# wiz16b8m4ct3_0_WIZ16B8M4CT3 register map
Vendor: Texas Instruments
Registers are 32-bit, read-write, reset 0x0 unless marked. A register's access mark holds for its fields unless they carry their own. Offsets are as the file gives them; [hi:lo] are bit positions; {n}, {i} and the like mark numbered series.

## wiz16b8m4ct3_0_WIZ16B8M4CT3 (part 2 of 12)
0x00 WIZ16B8M4CT3_CMN_PID_TYPE ro reset 0x7364
  [15:0] CMN_PID_TYPE_15_0 — Product type : This field contains the ASCII codes that represent the product type sd for SerDes.
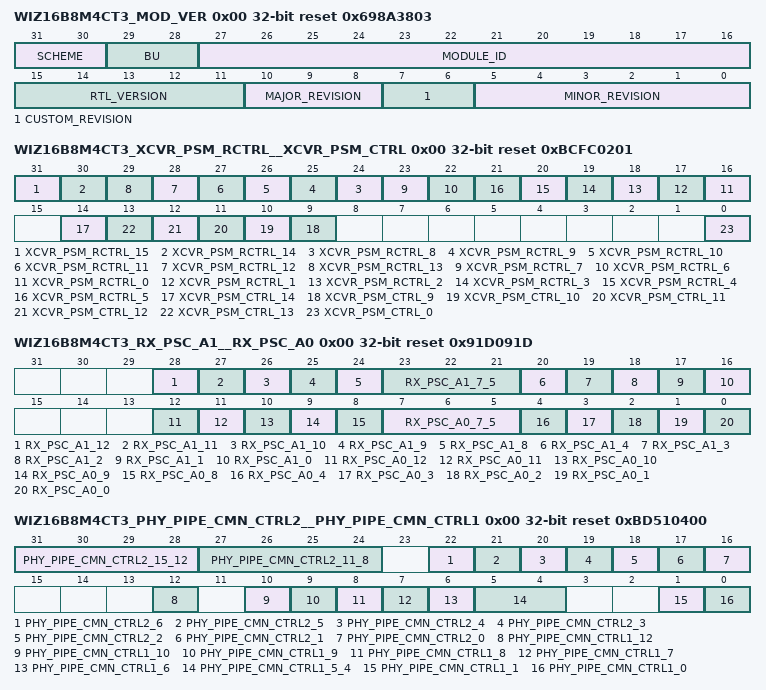
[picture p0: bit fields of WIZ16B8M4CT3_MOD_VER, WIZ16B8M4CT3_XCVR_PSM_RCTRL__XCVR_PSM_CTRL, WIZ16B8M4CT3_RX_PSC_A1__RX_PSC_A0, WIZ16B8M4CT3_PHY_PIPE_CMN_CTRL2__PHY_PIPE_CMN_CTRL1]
0x00 WIZ16B8M4CT3_MOD_VER ro reset 0x698A3803
  [31:30] SCHEME — Module Scheme
  [29:28] BU — Module Business Unit
  [27:16] MODULE_ID — WIZ16B8M4CT3 module ID.
  [15:11] RTL_VERSION
  [10:8] MAJOR_REVISION
  [7:6] CUSTOM_REVISION
  [5:0] MINOR_REVISION
0x00 WIZ16B8M4CT3_XCVR_PSM_RCTRL__XCVR_PSM_CTRL reset 0xBCFC0201
  [31] XCVR_PSM_RCTRL_15 — RX reset active ready : Controls the state the receiver reset is changed to when in the ready power state. 1'b0: Reset not active 1'b1: Reset active
  [30] XCVR_PSM_RCTRL_14 — RX reset active calibration : Controls the state the receiver reset is changed to when in the calibration power state. 1'b0: Reset not active 1'b1: Reset active
  [n+16] XCVR_PSM_RCTRL_{n} (n=8..13) — RX reset active A{n-8} : Controls the state the receiver reset is changed to when in the A{n-8} entry power state. 1'b0: Reset not active 1'b1: Reset active
  [23] XCVR_PSM_RCTRL_7 — TX reset active ready : Controls the state the transmitter reset is changed to when in the ready power state. 1'b0: Reset not active 1'b1: Reset active
  [22] XCVR_PSM_RCTRL_6 — TX reset active calibration : Controls the state the transmitter reset is changed to when in the calibration power state. 1'b0: Reset not active 1'b1: Reset active
  [n+16] XCVR_PSM_RCTRL_{n} (n=0..5) — TX reset active A{n} : Controls the state the transmitter reset is changed to when in the A{n} entry power state. 1'b0: Reset not active 1'b1: Reset active
  [14] XCVR_PSM_CTRL_14 — Bypass A0 in delay from PSM ready : When this bit is active (1'b1), the A0 input delay is bypassed when transitioning from the PSM ready state to the A0 power state. The result of this is the amount of time spent in the A0 in delay state is the value specified in the A0 in bypass timer register. The intention of this bit is to bypass the delay for cases when the required analog components being controlled are already enabled in the ready power state, and no additional delay is required when transitioning to the A0 power state.
  [n] XCVR_PSM_CTRL_{n} (n=9..13) — Bypass A0 in delay from A{n-8} : When this bit is active (1'b1), the A0 input delay is bypassed when transitioning from the A{n-8} to the A0 power state. The result of this is the amount of time spent in the A0 in delay state is the value specified in the A0 in bypass timer register. The intention of this bit is to bypass the delay for cases when the required analog components being controlled are already enabled in the A{n-8} power state, and no additional delay is required when transitioning to the A0 power state.
  [0] XCVR_PSM_CTRL_0 — Reserved - spare (must remain set to 1'b1).
0x00 WIZ16B8M4CT3_RX_PSC_A1__RX_PSC_A0 reset 0x91D091D
  [28] RX_PSC_A1_12 — RX signal detect enable extend control
  [27] RX_PSC_A1_11 — RX signal detect filter enable
  [26] RX_PSC_A1_10 — RX LFPS detect filter enable
  [25] RX_PSC_A1_9 — Reserved - spare
  [24] RX_PSC_A1_8 — RX signal detect enable
  [23:21] RX_PSC_A1_7_5 — Reserved - spare
  [20] RX_PSC_A1_4 — RX equalizer engine enable
  [19] RX_PSC_A1_3 — RX DFE equalization enable.
  [18] RX_PSC_A1_2 — RX PI enable
  [17] RX_PSC_A1_1 — RX e path enable (calibration and eye surf only)
  [16] RX_PSC_A1_0 — RX enable
  [12] RX_PSC_A0_12 — RX signal detect enable extend control: Specifies which power states the rx_sig_det_en_ext signal is considered valid in and can be used to force the signal detect functions to remain on.
  [11] RX_PSC_A0_11 — RX signal detect filter enable: Enables the receiver signal detect filter function in the digital receiver controller.
  [10] RX_PSC_A0_10 — RX LFPS detect filter enable: Enables the receiver LFPS detect filter function in the digital receiver controller.
  [9] RX_PSC_A0_9 — Reserved - spare
  [8] RX_PSC_A0_8 — RX signal detect enable: Enables the receiver signal detect function. This drives the rxda_sd_en signal going to the analog. Note: This bit needs to be active for LFPS detect functions to work, because these functions share the same analog circuits.
  [7:5] RX_PSC_A0_7_5 — Reserved - spare
  [4] RX_PSC_A0_4 — RX equalizer engine enable: Specifies which power state the REE runs in. 1'b0: Disabled 1'b1: Enabled
  [3] RX_PSC_A0_3 — RX DFE equalization enable: Enables the receiver DFE equalization circuits, via the rxda_dfe_eq_enable signal.
  [2] RX_PSC_A0_2 — RX PI enable: Enables the receiver circuits related to the PI and associated clocking components.
  [1] RX_PSC_A0_1 — RX e path enable (calibration and eye surf only) : Enables the receiver circuits related to the eye plot PI and e path deserializer for calibration and eye surf.
  [0] RX_PSC_A0_0 — RX enable: Enables the receiver circuits related to the CDRLF, Sampler, FE, and Deserializer.
0x00 WIZ16B8M4CT3_PHY_PIPE_CMN_CTRL2__PHY_PIPE_CMN_CTRL1 access not given reset 0xBD510400
  [31:28] PHY_PIPE_CMN_CTRL2_15_12 rw — USB SuperSpeed Tx LFPS Stretch : Minimum number of data rate clock cycles in which PMA tx_lfps_en signal is asserted for USB SuperSpeed rate. Number of data rate clock cycles must be X 1 PMA RefClk cycle.
  [27:24] PHY_PIPE_CMN_CTRL2_11_8 rw — USB SuperSpeedPlus Tx LFPS Stretch : Minimum number of data rate clock cycles in which PMA tx_lfps_en signal is asserted for USB SuperSpeedPlus rate. Number of data rate clock cycles must be X 1 PMA RefClk cycle.
  [22] PHY_PIPE_CMN_CTRL2_6 rw — PCIe PCS TX electrical idle pre release:When this bit is set, the TX electrical idle release to the PMA is advanced 1 cycle to allow the adjustment of the datapath timing
  [21] PHY_PIPE_CMN_CTRL2_5 rw — RX equaliser complete mask: When this bit is cleared, the PHY will return direction change of 0 when PMA indicates evaluation complete. Subsequent evaluation requests would clear the PMA iteration counters. When set high, the PMA equalization complete signal is ignored.
  [20] PHY_PIPE_CMN_CTRL2_4 rw — PCIe PCS EIOS cycle error mask: When this bit is enabled and the pipe rx interface is outputting an EIOS symbol, decode errors will be masked out
  [19] PHY_PIPE_CMN_CTRL2_3 rw — USB Gen 2 Bit Error Correction Disable: When this bit is high, bit error correction on SKP and SDS symbols is disabled.
  [18] PHY_PIPE_CMN_CTRL2_2 rw — USB PIPE3 Compatibility Mode enable : When this bit is set to 1, USB PIPE3 compatibility mode is enabled. In this mode, when operating in nominal empty Elasticity Buffer mode, when the EB buffer goes empty, instead of de-asserting PIPE RxDataValid, a USB SKIP OS is inserted into the data stream. This is the behavior as defined in PIPE version 3. When this bit is low, PIPE RxDataValid is de-asserted when the EB buffer goes empty, as recommended by PIPE version 4.
  [17] PHY_PIPE_CMN_CTRL2_1 rw — USB Loopback Slave Error Count disable: When this bit is set to 1, disables the error count for US loopback slave, such that the error count is not inserted into the BCNT OS.
  [16] PHY_PIPE_CMN_CTRL2_0 rw — USB Elasticity Buffer Re-align enable: When this bit is set to 1, when Rx for a USB link is initially started, the elasticity buffer is re-aligned to its idle point upon seeing 3 consecutive COMMAs (i.e. from TS1/TS2s) in the same relative bit position. The purpose of this is to re-align the elasticity buffer (i.e. CTC) after receiving the TSEQ data, which contains no SKIP OSs.
  [12] PHY_PIPE_CMN_CTRL1_12 — PHY APB access timeout: When set, an APB read/write request to PHY registers failed (i.e. timed out). When set, this bit is cleared upon read. (access RTR)
  [10] PHY_PIPE_CMN_CTRL1_10 rw — PCIe PCS Comma realign: This field controls the comma alignment state machine to re-align to new bit position without going to loss of sync state. The requirement of the new bit position should meet the number of COMMAs as per Symbol unlock count register definition. When new bit position is identified the comma alignment state machine remains in sync state with the alignment now locked to the new bit position. This field needs to be programmed during the PHY initialization routine before training sequences are received. The effect here is that pipe_rx_valid is not de-asserted upon re-alignment. When this bit is 0, pipe_rx_valid will be de-asserted upon loss of COMMA lock and subsequent re-alignment. Applies for PCIe Gen 1/2 and USB3.1 Gen 1 only. ()
  [9] PHY_PIPE_CMN_CTRL1_9 rw — Block alignment clear on EIOS : When set, upon receiving a PCIe EIOS, 128b/130b block alignment is reset regardless of Rx signal detect from the PMA (applies for PCIe Gen 3 only). ()
  [8] PHY_PIPE_CMN_CTRL1_8 rw — Comma alignment clear on EIOS : When set, upon receiving a PCIe EIOS, Comma Alignment is reset regardless of Rx signal detect from the PMA (applies for PCIe Gen 1/2 only). ()
  [7] PHY_PIPE_CMN_CTRL1_7 rw — Block alignment ignore Rx SigDetect : When set, 128b/13xb block alignment will not be reset due to loss of signal detection from the PMA (applies for PCIe Gen 3 and USB3.1 Gen 2 only). ()
  [6] PHY_PIPE_CMN_CTRL1_6 rw — Comma alignment ignore Rx SigDetect : When set, Comma alignment will not be reset due to loss of signal detection from the PMA (applies for PCIe Gen 1/2 and USB3.1 Gen 1 only). ()
  [5:4] PHY_PIPE_CMN_CTRL1_5_4 rw — Rx signal detect delay : Selects the number of clock cycles of delay to add to the PMA signal detect when the bit alignment blocks should be reset after losing signal. ()
  [1] PHY_PIPE_CMN_CTRL1_1 rw — RefClk disable override: 1 = overrides turning off reference clock receiver by forcing cmn_refclk_disable PMA input low. 0 = normal control of cmn_refclk_disable PMA input by PHY logic. ()
  [0] PHY_PIPE_CMN_CTRL1_0 rw — PHY RefClk enable input ingnore : 0 = ignore phy_en_refclk PHY input (forces low internally). 1 = phy_en_refclk_used as specified for controling enable/disable of cmn_refclk_Xp/mX. ()
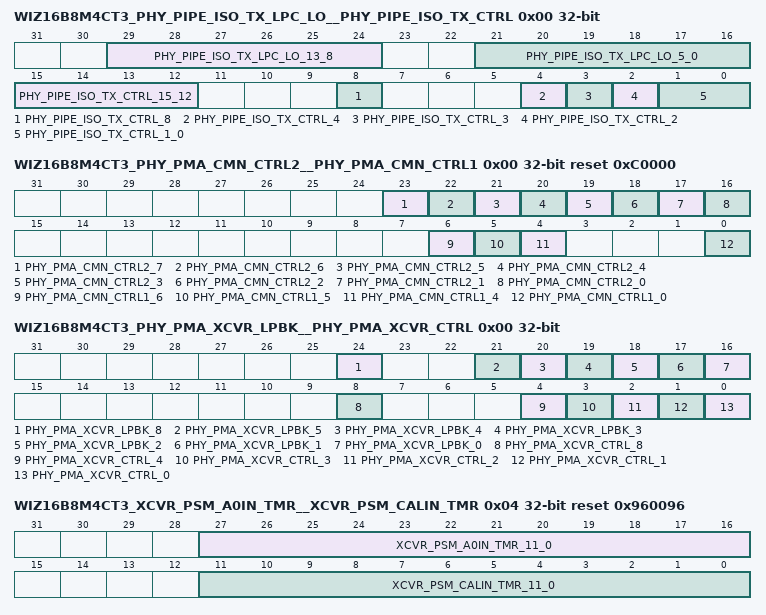
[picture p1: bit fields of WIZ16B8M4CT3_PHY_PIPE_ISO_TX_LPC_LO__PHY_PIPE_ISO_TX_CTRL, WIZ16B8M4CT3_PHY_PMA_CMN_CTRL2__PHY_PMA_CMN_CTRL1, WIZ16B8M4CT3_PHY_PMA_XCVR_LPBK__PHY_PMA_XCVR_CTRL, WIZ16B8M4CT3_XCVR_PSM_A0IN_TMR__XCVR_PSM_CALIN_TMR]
0x00 WIZ16B8M4CT3_PHY_PIPE_ISO_TX_LPC_LO__PHY_PIPE_ISO_TX_CTRL access per field
  [29:24] PHY_PIPE_ISO_TX_LPC_LO_13_8 ro — Current value of pipe_tx_local_tx_preset_coefficients[11:6] for the associated lane when PHY_PCS_ISO_TX_LPC_HI[15] == 1. Otherwise, 0.
  [21:16] PHY_PIPE_ISO_TX_LPC_LO_5_0 ro — Current value of pipe_tx_local_tx_preset_coefficients[5:0] for the associated lane when PHY_PCS_ISO_TX_LPC_HI[15] == 1. Otherwise, 0.
  [15:12] PHY_PIPE_ISO_TX_CTRL_15_12 rw — Drives pipe_tx_data_k PHY input for the associated lane when in PHY macro and PMA isolation modes.
  [8] PHY_PIPE_ISO_TX_CTRL_8 rw — Drives pipe_tx_ones_zeros input for the associated lane when in PHY macro and PMA isolation modes.
  [4] PHY_PIPE_ISO_TX_CTRL_4 rw — Drives pipe_tx_elec_idle PHY input for the associated lane when in PHY macro and PMA isolation modes
  [3] PHY_PIPE_ISO_TX_CTRL_3 rw — Drives pipe_tx_128b_enc_byp PHY input for the associated lane when in PHY macro and PMA isolation modes.
  [2] PHY_PIPE_ISO_TX_CTRL_2 rw — Drives pipe_tx_compliance PHY input for the associated lane when in PHY macro and PMA isolation modes.
  [1:0] PHY_PIPE_ISO_TX_CTRL_1_0 rw — Drives pipe_tx_pattern PHY input for the associated lane when in PHY macro and PMA isolation modes.
0x00 WIZ16B8M4CT3_PHY_PMA_CMN_CTRL2__PHY_PMA_CMN_CTRL1 access per field reset 0xC0000
  [23] PHY_PMA_CMN_CTRL2_7 ro — Current value of cmn_pll1_locked PMA output
  [22] PHY_PMA_CMN_CTRL2_6 ro — Current value of cmn_pll0_locked PMA output
  [21] PHY_PMA_CMN_CTRL2_5 ro — Current value of cmn_pll1_clk_en_ack PMA output
  [20] PHY_PMA_CMN_CTRL2_4 ro — Current value of cmn_pll0_clk_en_ack PMA output
  [19] PHY_PMA_CMN_CTRL2_3 ro — Current value of cmn_pll1_disabled PMA output
  [18] PHY_PMA_CMN_CTRL2_2 ro — Current value of cmn_pll0_disabled PMA output
  [17] PHY_PMA_CMN_CTRL2_1 ro — Current value of cmn_pll1_ready PMA output
  [16] PHY_PMA_CMN_CTRL2_0 ro — Current value of cmn_pll0_ready PMA output
  [6] PHY_PMA_CMN_CTRL1_6 rw — Drives cmn_refclk_rcv_out_en PMA input
  [5] PHY_PMA_CMN_CTRL1_5 ro — Current value of cmn_macro_suspend_ack PMA output
  [4] PHY_PMA_CMN_CTRL1_4 ro — Current value of cmn_refclk_active PMA output
  [0] PHY_PMA_CMN_CTRL1_0 ro — Current value of cmn_ready pin PMA output
0x00 WIZ16B8M4CT3_PHY_PMA_XCVR_LPBK__PHY_PMA_XCVR_CTRL access per field
  [24] PHY_PMA_XCVR_LPBK_8 rw — Drives the tx_bist_hold PMA input for all lanes in the associated link (i.e. the bit associated with the master lane of the link drives all lanes in the link). Synchronized to transmit data rate clock.
  [21] PHY_PMA_XCVR_LPBK_5 rw — Drives the xcvr_lpbk_fe_parallel_en PMA input for the associated lane.
  [20] PHY_PMA_XCVR_LPBK_4 rw — Drives the xcvr_lpbk_ne_parallel_en PMA input for the associated lane.
  [19] PHY_PMA_XCVR_LPBK_3 rw — Drives the xcvr_lpbk_recovered_clk_en PMA input for the associated lane.
  [18] PHY_PMA_XCVR_LPBK_2 rw — Drives the xcvr_lpbk_line_en PMA input for the associated lane.
  [17] PHY_PMA_XCVR_LPBK_1 rw — Drives the xcvr_lpbk_isi_gen_en PMA input for the associated lane.
  [16] PHY_PMA_XCVR_LPBK_0 rw — Drives the xcvr_lpbk_serial_en PMA input for the associated lane.
  [8] PHY_PMA_XCVR_CTRL_8 rw — Drives the tx_differential_invert PMA input for the associated lane.
  [4] PHY_PMA_XCVR_CTRL_4 ro — Current value of rx_cdrlf_fphl_locked PMA output for the associated lane.
  [3] PHY_PMA_XCVR_CTRL_3 ro — Current value of rx_bist_status PMA output for the associated lane.
  [2] PHY_PMA_XCVR_CTRL_2 ro — Current value of rx_bist_err_toggle PMA output for the associated lane.
  [1] PHY_PMA_XCVR_CTRL_1 ro — Current value of rx_bist_sync PMA output for the associated lane.
  [0] PHY_PMA_XCVR_CTRL_0 rw — Drives the rx_differential_invert PMA input for the associated lane.
0x04 WIZ16B8M4CT3_CMN_PID_NUM ro reset 0x8050000
  [31:16] CMN_PID_NUM_15_0 — Product number : This field contains the binary coded decimal numbers that represent the product number. The following are the possible reset values for this field. 16'h0801: SD0801 16'h0802: SD0802 16'h0803: SD0803 16'h0804: SD0804 16'h0804: SD0805
0x04 WIZ16B8M4CT3_SERDES_CTRL
  [31] POR_EN — The por_en allows the system to place the SERDES in a reset state, Access to the SERDES registers are ignored.
0x04 WIZ16B8M4CT3_XCVR_PSM_A0IN_TMR__XCVR_PSM_CALIN_TMR reset 0x960096
  [27:16] XCVR_PSM_A0IN_TMR_11_0 — A0 in delay state timer value : Value used for the timer when the power state machine is in the A0 in delay state, unless the timer is bypassed under the control of the bypass A0 bits in the Power state machine control register. This timer delay is specified as the number of PSM clocks to count to implement the time required for tpsm_A0_in_del. Note, the smallest value this field is allowed to be is 12'h001. With that said, setting this field to a value smaller than the reset value will likely result in incorrect function.
  [11:0] XCVR_PSM_CALIN_TMR_11_0 — PSM calibration in delay state timer value : Value used for the timer when the power state machine is in the PSM calibration in delay state. This timer delay is specified as the number of PSM clocks to count to implement the time required for tpsm_lane_cal_in_del. Note, the smallest value this field is allowed to be is 12'h001. With that said, setting this field to a value smaller than the reset value will likely result in incorrect function.
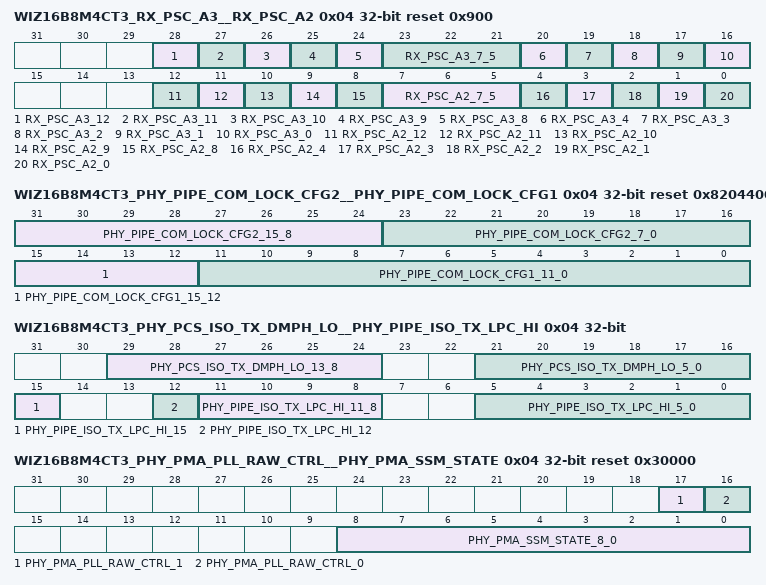
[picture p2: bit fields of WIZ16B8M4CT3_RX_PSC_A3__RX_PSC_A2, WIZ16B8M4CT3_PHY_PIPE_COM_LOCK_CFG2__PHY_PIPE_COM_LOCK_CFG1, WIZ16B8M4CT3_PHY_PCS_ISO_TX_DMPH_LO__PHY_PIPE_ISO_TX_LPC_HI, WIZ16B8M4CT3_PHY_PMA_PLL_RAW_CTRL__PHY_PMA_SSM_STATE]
0x04 WIZ16B8M4CT3_RX_PSC_A3__RX_PSC_A2 reset 0x900
  [28] RX_PSC_A3_12 — RX signal detect enable extend control
  [27] RX_PSC_A3_11 — RX signal detect filter enable
  [26] RX_PSC_A3_10 — RX LFPS detect filter enable
  [25] RX_PSC_A3_9 — Reserved - spare
  [24] RX_PSC_A3_8 — RX signal detect enable
  [23:21] RX_PSC_A3_7_5 — Reserved - spare
  [20] RX_PSC_A3_4 — RX equalizer engine enable
  [19] RX_PSC_A3_3 — RX DFE equalization enable.
  [18] RX_PSC_A3_2 — RX PI enable
  [17] RX_PSC_A3_1 — RX e path enable (calibration and eye surf only)
  [16] RX_PSC_A3_0 — RX enable
  [12] RX_PSC_A2_12 — RX signal detect enable extend control
  [11] RX_PSC_A2_11 — RX signal detect filter enable
  [10] RX_PSC_A2_10 — RX LFPS detect filter enable
  [9] RX_PSC_A2_9 — Reserved - spare
  [8] RX_PSC_A2_8 — RX signal detect enable
  [7:5] RX_PSC_A2_7_5 — Reserved - spare
  [4] RX_PSC_A2_4 — RX equalizer engine enable
  [3] RX_PSC_A2_3 — RX DFE equalization enable.
  [2] RX_PSC_A2_2 — RX PI enable
  [1] RX_PSC_A2_1 — RX e path enable (calibration and eye surf only)
  [0] RX_PSC_A2_0 — RX enable
0x04 WIZ16B8M4CT3_PHY_PIPE_COM_LOCK_CFG2__PHY_PIPE_COM_LOCK_CFG1 reset 0x8204400
  [31:24] PHY_PIPE_COM_LOCK_CFG2_15_8 — PCIe PCS Comma lock count fast: The number of COMMA symbols that needs to be seen in the same bit position for the comma state machine to lock. This field is used while the PCS is in P0 state after an EIOS has been seen, ie detecting FTS
  [23:16] PHY_PIPE_COM_LOCK_CFG2_7_0 — PCIe PCS Comma lock count: The number of COMMA symbols that needs to be seen in the same bit position for the comma state machine to lock. This field is used while the PCS is transitioning back to the P0 power state.
  [15:12] PHY_PIPE_COM_LOCK_CFG1_15_12 — PCIe PCS Comma unlock count: The number of COMMA symbols that need to be seen in the wrong bit position before the comma alignment state machine will transition to RESYNC or LOS state
  [11:0] PHY_PIPE_COM_LOCK_CFG1_11_0 — PCIe PCS Comma full lock count: The number of COMMA symbols that need to be seen in the same bit position for the comma alignment state machine to lock. The field is used for initial reset lock.
0x04 WIZ16B8M4CT3_PHY_PCS_ISO_TX_DMPH_LO__PHY_PIPE_ISO_TX_LPC_HI access per field
  [29:24] PHY_PCS_ISO_TX_DMPH_LO_13_8 rw — Drives pipe_tx_deemph[11:6] PHY input for the associated lane when in PHY macro and PMA isolation mode.
  [21:16] PHY_PCS_ISO_TX_DMPH_LO_5_0 rw — Drives pipe_tx_deemph[5:0] PHY input for the associated lane when in PHY macro and PMA isolation mode.
  [15] PHY_PIPE_ISO_TX_LPC_HI_15 ro — Set upon assertion of pipe_tx_local_tx_coeff_vld PHY output for the associated lane. Cleared upon writing PHY_PCS_ISO_TX_LPC_HI[12] with a 0.
  [12] PHY_PIPE_ISO_TX_LPC_HI_12 rw — Drives pipe_tx_get_local_preset_coef PHY output for the associated lane when in PHY macro and PMA isolation modes
  [11:8] PHY_PIPE_ISO_TX_LPC_HI_11_8 rw — Drives pipe_tx_local_preset_index PHY output for the associated lane when in PHY macro and PMA isolation modes.
  [5:0] PHY_PIPE_ISO_TX_LPC_HI_5_0 ro — Current value of pipe_tx_local_tx_preset_coefficients[17:12] for the associated lane when PHY_PCS_ISO_TX_LPC_HI[15] == 1. Otherwise, 0.
0x04 WIZ16B8M4CT3_PHY_PMA_PLL_RAW_CTRL__PHY_PMA_SSM_STATE access per field reset 0x30000
  [17] PHY_PMA_PLL_RAW_CTRL_1 rw — Raw SerDes PLL1 control : When set to 1, cmn_pll1_en PMA input is controlled by PHY logic. When set to 0, cmn_pll1_en PMA input is forced low. When PLL1 is driving lanes configured for Raw SerDes operation, this bit allows manual' enable/disable of PLL1 to allow reconfiguration of the PLL for a different data rate. The PHY logic drives cmn_pll1_en high unless the PHY is configured to operation on PLL0 only (PHY_PLL_CFG[1] == 0).
  [16] PHY_PMA_PLL_RAW_CTRL_0 rw — Raw SerDes PLL0 control : When set to 1, cmn_pll0_en PMA input is controlled by PHY logic. When set to 0, cmn_pll0_en PMA input is forced low. When PLL0 is driving lanes configured for Raw SerDes operation, this bit allows manual' enable/disable of PLL0 to allow reconfiguration of the PLL for a different data rate. The PHY logic drives cmn_pll0_en high except when the PHY is configured for single link PCIe mode and is performing a rate change between PCIe Gen 1/2 and PCIe Gen 3 (PHY_PLL_CFG[0] == 1). However, PCIe is only supported for PIPE mode and not applicable when PLL0 is driving lanes configured for Raw SerDes operation.
  [8:0] PHY_PMA_SSM_STATE_8_0 ro — PMA SSM : Current state of the PMA startup state machine. PMA output (Not re-synchronized to apb_pclk)
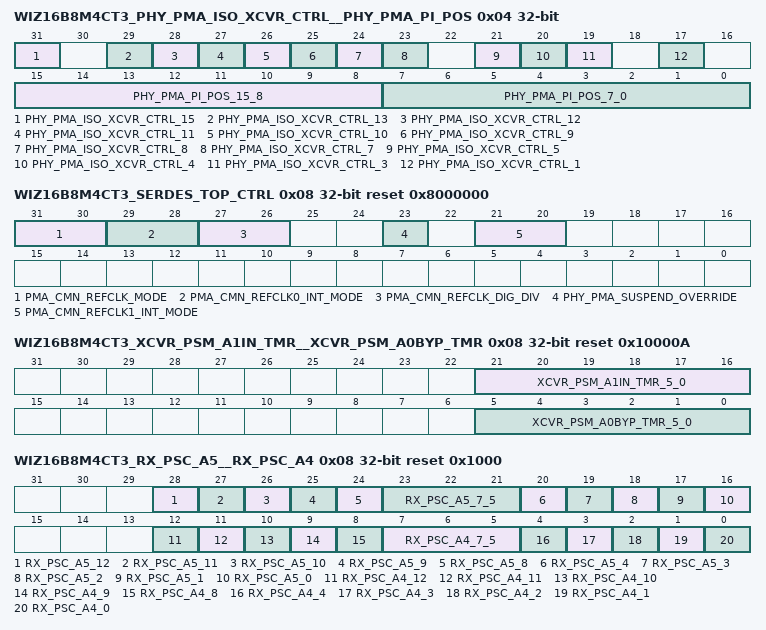
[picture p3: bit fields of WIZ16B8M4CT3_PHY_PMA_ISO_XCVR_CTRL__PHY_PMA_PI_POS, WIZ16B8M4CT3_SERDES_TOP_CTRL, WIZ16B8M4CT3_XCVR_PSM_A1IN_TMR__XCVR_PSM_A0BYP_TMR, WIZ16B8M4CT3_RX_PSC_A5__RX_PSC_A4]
0x04 WIZ16B8M4CT3_PHY_PMA_ISO_XCVR_CTRL__PHY_PMA_PI_POS access per field
  [31] PHY_PMA_ISO_XCVR_CTRL_15 ro — Current value of xcvr_pll_clk_en_ack PMA output for the associated lane.
  [29] PHY_PMA_ISO_XCVR_CTRL_13 rw — Drives tx_lfps_en PMA input for the associated lane when in PMA isolation mode.
  [28] PHY_PMA_ISO_XCVR_CTRL_12 rw — Drives tx_elec_idle PMA input for the associated lane when in PMA isolation mode or PHY isolation mode and lane is configured for Raw SerDes mode.
  [27] PHY_PMA_ISO_XCVR_CTRL_11 ro — Current value of tx_rcv_detected PMA output for the associated lane. (Not re-synchronized to apb_pclk)
  [26] PHY_PMA_ISO_XCVR_CTRL_10 ro — Current value of tx_rcv_detect_done PMA ouptut for the associated lane.
  [25] PHY_PMA_ISO_XCVR_CTRL_9 rw — Drives tx_rcv_detect_en PMA input for the associated lane when in PMA isolation mode or PHY isolation mode and lane is configured for Raw SerDes mode.
  [24] PHY_PMA_ISO_XCVR_CTRL_8 rw — Drives xcvr_link_reset_n PMA input for the associated lane when in PMA isolation mode.
  [23] PHY_PMA_ISO_XCVR_CTRL_7 rw — Drives xcvr_pll_clk_en PMA input for the associated lane when in PMA isolation mode or PHY isolation mode and lane is configured for Raw SerDes mode.
  [21] PHY_PMA_ISO_XCVR_CTRL_5 rw — Drives xcvr_lane_suspend PMA input for the associated lane when in PMA isolation mode.
  [20] PHY_PMA_ISO_XCVR_CTRL_4 ro — Current value of rx_lfps_detect PMA output for the associated lane.
  [19] PHY_PMA_ISO_XCVR_CTRL_3 ro — Current value of rx_signal_detect PMA output for the associated lane.
  [17] PHY_PMA_ISO_XCVR_CTRL_1 rw — Drives rx_termination PMA input for the associated lane when in PMA isolation mode or PHY isolation mode and lane is configured for Raw SerDes mode.
  [15:8] PHY_PMA_PI_POS_15_8 ro — Current value of rx_pi_val PMA output for the associated lane.
  [7:0] PHY_PMA_PI_POS_7_0 ro — Current value of rx_eye_plot_pi_val PMA output for the associated lane.
0x08 WIZ16B8M4CT3_CMN_PID_REV ro reset 0x200
  [15:0] CMN_PID_REV_15_0 — Product revision : This field contains the binary coded decimal numbers that represent the product revision.
0x08 WIZ16B8M4CT3_SERDES_TOP_CTRL reset 0x8000000
  [31:30] PMA_CMN_REFCLK_MODE — The PMA common differential reference clock mode - Sets the mode of operation for differential reference clock input. Must be set before the de-assertion of apb_preset_n/phy_reset_n. 2'b00 - 100 MHz and greater differential reference clock. 2'b01 - 100 MHz and greater singled ended DC coupled test reference clock. 2'b10 - Less than 100 MHz differential reference clock. 2'b11 - Less than 100 MHz single ended DC coupled test reference clock.
  [29:28] PMA_CMN_REFCLK0_INT_MODE — The PMA common internal reference clock mode - Sets the mode of operation for internal reference clock input (pma_cmn_refclk0_int (core_ref_clk)). Must be set before the de-assertion of apb_preset_n/phy_reset_n. 2'b00 - Reserved 2'b01 - 100 MHz and greater reference clock 2'b10 - Reserved 2'b11 - Less than 100 MHz reference clock
  [27:26] PMA_CMN_REFCLK_DIG_DIV — The PMA common reference clock digital divide ratio select - Must be set before the de-assertion of apb_preset_n/phy_reset_n. 2'b00 - Divide by 1 (set for reference clock in the 19.2 to 27MHz range) 2'b01 - Divide by 2 (Reserved) 2'b10 - Divide by 4 (set for 100 MHz reference clock) 2'b11 - Divide by 8 (Reserved)
  [23] PHY_PMA_SUSPEND_OVERRIDE — The PHY PMA common suspend override enable: 1 = disables suspending the PMA common when all links are in low power state (L1 SS, PCIe P2, USB P3, power down disabled, etc.). 0 = PMA common will be suspended when all links are in low power state. Driving this pin high has no effect if the PMA common is already suspended or is in the process of being suspended (i.e. it will not force the PMA common to resume). It only prevents the start of suspending the PMA common. However, if this pin is de-asserted when all links are in low power state, the PMA common will then be suspended.
  [21:20] PMA_CMN_REFCLK1_INT_MODE — The PMA common internal reference clock mode - Sets the mode of operation for internal reference clock input (pma_cmn_refclk1_int (core_ref1_clk)). Must be set before the de-assertion of apb_preset_n/phy_reset_n. 2'b00 - Reserved 2'b01 - 100 MHz and greater reference clock 2'b10 - Reserved 2'b11 - Less than 100 MHz reference clock
0x08 WIZ16B8M4CT3_XCVR_PSM_A1IN_TMR__XCVR_PSM_A0BYP_TMR reset 0x10000A
  [21:16] XCVR_PSM_A1IN_TMR_5_0 — A1 in delay state timer value : Value used for the timer when the power state machine is in the A1 in delay state. This timer delay is specified as the number of PSM clocks to count to implement the time required for tpsm_A1_in_del. Note, the smallest value this field is allowed to be is 6'h01. With that said, setting this field to a value smaller than the reset value will likely result in incorrect function.
  [5:0] XCVR_PSM_A0BYP_TMR_5_0 — A0 in delay state bypass timer value : Value used for the timer when the power state machine is in the A0 in delay state and the timer is bypassed under the control of the bypass A0 bits in the Power state machine control register. This timer delay is specified as the number of PSM clocks to count to implement the time required for tpsm_A0_in_byp. Note, the smallest value this field is allowed to be is 6'h01. With that said, setting this field to a value smaller than the reset value will likely result in incorrect function.
0x08 WIZ16B8M4CT3_RX_PSC_A5__RX_PSC_A4 reset 0x1000
  [28] RX_PSC_A5_12 — RX signal detect enable extend control
  [27] RX_PSC_A5_11 — RX signal detect filter enable
  [26] RX_PSC_A5_10 — RX LFPS detect filter enable
  [25] RX_PSC_A5_9 — Reserved - spare
  [24] RX_PSC_A5_8 — RX signal detect enable
  [23:21] RX_PSC_A5_7_5 — Reserved - spare
  [20] RX_PSC_A5_4 — RX equalizer engine enable
  [19] RX_PSC_A5_3 — RX DFE equalization enable.
  [18] RX_PSC_A5_2 — RX PI enable
  [17] RX_PSC_A5_1 — RX e path enable (calibration and eye surf only)
  [16] RX_PSC_A5_0 — RX enable
  [12] RX_PSC_A4_12 — RX signal detect enable extend control
  [11] RX_PSC_A4_11 — RX signal detect filter enable
  [10] RX_PSC_A4_10 — RX LFPS detect filter enable
  [9] RX_PSC_A4_9 — Reserved - spare
  [8] RX_PSC_A4_8 — RX signal detect enable
  [7:5] RX_PSC_A4_7_5 — Reserved - spare
  [4] RX_PSC_A4_4 — RX equalizer engine enable
  [3] RX_PSC_A4_3 — RX DFE equalization enable.
  [2] RX_PSC_A4_2 — RX PI enable
  [1] RX_PSC_A4_1 — RX e path enable (calibration and eye surf only)
  [0] RX_PSC_A4_0 — RX enable
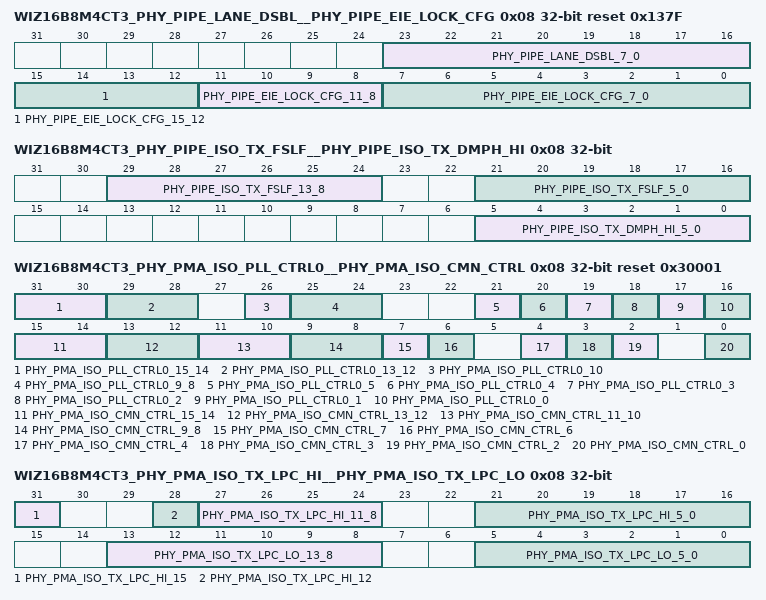
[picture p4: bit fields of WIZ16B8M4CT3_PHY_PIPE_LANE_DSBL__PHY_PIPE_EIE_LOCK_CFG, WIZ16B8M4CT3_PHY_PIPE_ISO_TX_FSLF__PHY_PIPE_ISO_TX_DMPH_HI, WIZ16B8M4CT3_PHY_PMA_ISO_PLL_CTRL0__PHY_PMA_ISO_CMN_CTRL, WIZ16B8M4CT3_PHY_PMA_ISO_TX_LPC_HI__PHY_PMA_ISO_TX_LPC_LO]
0x08 WIZ16B8M4CT3_PHY_PIPE_LANE_DSBL__PHY_PIPE_EIE_LOCK_CFG reset 0x137F
  [23:16] PHY_PIPE_LANE_DSBL_7_0 — PIPE lane disable: Each bit corresponds to a lane (i.e. bit [0] -X lane 0, bit [1] -X lane 1, etc). When set the corresponding PIPE lane is disabled. Lanes that are disabled will transmit electrical idle and will not return any data on PIPE Rx interface. Used to disable unused lanes in a multi-lane PCIe link. (The PMA transceiver corresponding to lane will be placed in suspend.)
  [15:12] PHY_PIPE_EIE_LOCK_CFG_15_12 — EIE lock count fast: The number of EIEOS blocks that need to be seen in the same bit postion for the alignment state machine to lock for Gen3/4. The field is used while the PCS is in P0 state after an EIEOS has been seen
  [11:8] PHY_PIPE_EIE_LOCK_CFG_11_8 — EIE lock count : The number of EIEOS blocks that need to be seen in the same bit postion for the alignment state machine to lock for Gen3/4. The field is used while the PCS is transitioning out of a power state change and not performing a rate change
  [7:0] PHY_PIPE_EIE_LOCK_CFG_7_0 — EIE full lock count: The number of EIEOS blocks that need to be seen in the same bit postion for the alignment state machine to lock for Gen3/4. The field is used for initial after reset lock or lock after a rate change
0x08 WIZ16B8M4CT3_PHY_PIPE_ISO_TX_FSLF__PHY_PIPE_ISO_TX_DMPH_HI access per field
  [29:24] PHY_PIPE_ISO_TX_FSLF_13_8 ro — Current value of pipe_tx_local_fs PHY output for the associated lane. (Not re-synchronized to apb_pclk)
  [21:16] PHY_PIPE_ISO_TX_FSLF_5_0 ro — Current value of pipe_tx_local_lf PHY output for the associated lane. (Not re-synchronized to apb_pclk)
  [5:0] PHY_PIPE_ISO_TX_DMPH_HI_5_0 rw — Drives pipe_tx_deemph[17:12] PHY input for the associated lane when in PHY macro and PMA isolation modes.
0x08 WIZ16B8M4CT3_PHY_PMA_ISO_PLL_CTRL0__PHY_PMA_ISO_CMN_CTRL access per field reset 0x30001
  [31:30] PHY_PMA_ISO_PLL_CTRL0_15_14 rw — Drives cmn_pll1_ref_clk_sel PMA input when in PHY macro or PMA isolation mode.
  [29:28] PHY_PMA_ISO_PLL_CTRL0_13_12 rw — Drives cmn_pll0_ref_clk_sel PMA input when in PHY macro or PMA isolation mode.
  [26] PHY_PMA_ISO_PLL_CTRL0_10 rw — Drives cmn_ref_clk_term_en PMA input when in PHY macro or PMA isolation modes
  [25:24] PHY_PMA_ISO_PLL_CTRL0_9_8 rw — Drives cmn_ref_clk_dig_sel PMA input when in PHY macro or PMA isolation modes
  [21] PHY_PMA_ISO_PLL_CTRL0_5 rw — Drives cmn_pll1_mode_sel PMA input when in PMA isolation mode.
  [20] PHY_PMA_ISO_PLL_CTRL0_4 rw — Drives cmn_pll0_mode_sel PMA input when in PMA isolation mode.
  [19] PHY_PMA_ISO_PLL_CTRL0_3 rw — Drives cmn_pll1_clk_en PMA input when in PMA isolation mode
  [18] PHY_PMA_ISO_PLL_CTRL0_2 rw — Drives cmn_pll0_clk_en PMA input when in PMA isolation mode
  [17] PHY_PMA_ISO_PLL_CTRL0_1 rw — Drives cmn_pll1_en PMA input when in PMA isolation mode
  [16] PHY_PMA_ISO_PLL_CTRL0_0 rw — Drives cmn_pll0_en PMA input when in PMA isolation mode
  [15:14] PHY_PMA_ISO_CMN_CTRL_15_14 rw — Drives cmn_ref_clk1_int_mode PMA input when in PHY macro and PMA isolation modes.
  [13:12] PHY_PMA_ISO_CMN_CTRL_13_12 rw — Drives cmn_ref_clk0_int_mode PMA input when in PHY macro and PMA isolation modes.
  [11:10] PHY_PMA_ISO_CMN_CTRL_11_10 rw — Drives cmn_ref_clk_dig_div PMA input when in PHY macro or PMA isolation modes
  [9:8] PHY_PMA_ISO_CMN_CTRL_9_8 rw — Drives cmn_ref_clk0_mode PMA input when in PHY macro and PMA isolation modes.
  [7] PHY_PMA_ISO_CMN_CTRL_7 ro — Current value of cmn_clock_stop_ack PMA output.
  [6] PHY_PMA_ISO_CMN_CTRL_6 rw — Drives cmn_clock_stop_req PMA input when in PMA isolation mode
  [4] PHY_PMA_ISO_CMN_CTRL_4 rw — Drives cmn_ref_clk0_clk_gate_en PMA input when in PMA isolation mode.
  [3] PHY_PMA_ISO_CMN_CTRL_3 rw — Drives cmn_refclk_disable PMA input when in PMA isolation mode.
  [2] PHY_PMA_ISO_CMN_CTRL_2 rw — Drives cmn_macro_suspend_req PMA input when in PMA isolation mode.
  [0] PHY_PMA_ISO_CMN_CTRL_0 rw — Drives cmn_reset_n PMA input when in PMA isolation mode.
0x08 WIZ16B8M4CT3_PHY_PMA_ISO_TX_LPC_HI__PHY_PMA_ISO_TX_LPC_LO access per field
  [31] PHY_PMA_ISO_TX_LPC_HI_15 ro — Current value of tx_local_preset_coef_valid PMA output for the associated lane.
  [28] PHY_PMA_ISO_TX_LPC_HI_12 rw — Drives tx_get_local_preset_coef PMA input for the associated lane when in PMA isolation mode or PHY isolation mode and lane is configured for Raw SerDes mode.
  [27:24] PHY_PMA_ISO_TX_LPC_HI_11_8 rw — Drives tx_local_preset_index PMA input for the associated lane when in PMA isolation mode or PHY isolation mode and lane is configured for Raw SerDes mode.
  [21:16] PHY_PMA_ISO_TX_LPC_HI_5_0 ro — Value of tx_local_tx_preset_coef[17:12] PMA output for the associated lane captured upon assertion of tx_local_preset_coef_valid for the associated lane. Cleared upon read.
  [13:8] PHY_PMA_ISO_TX_LPC_LO_13_8 ro — Value of tx_local_tx_preset_coef[11:6] PMA output for the associated lane captured upon assertion of tx_local_preset_coef_valid for the associated lane. Cleared upon read.
  [5:0] PHY_PMA_ISO_TX_LPC_LO_5_0 ro — Value of tx_local_tx_preset_coef[5:0] PMA output for the associated lane captured upon assertion of tx_local_preset_coef_valid for the associated lane. Cleared upon read.
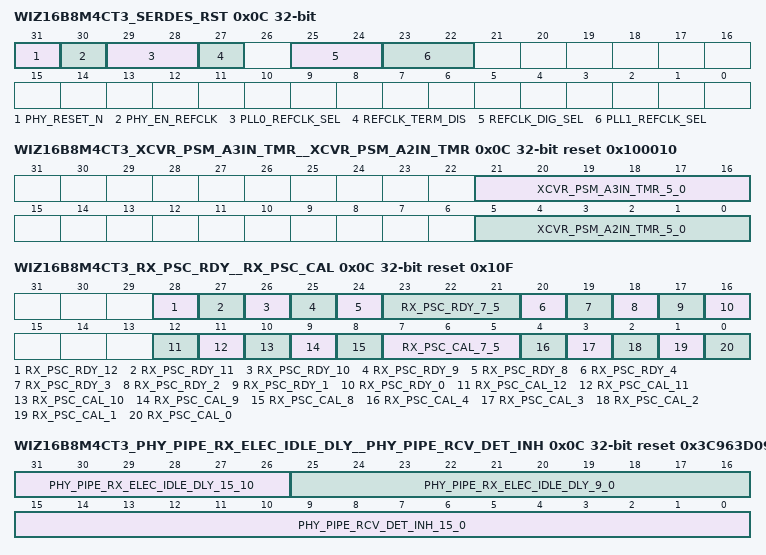
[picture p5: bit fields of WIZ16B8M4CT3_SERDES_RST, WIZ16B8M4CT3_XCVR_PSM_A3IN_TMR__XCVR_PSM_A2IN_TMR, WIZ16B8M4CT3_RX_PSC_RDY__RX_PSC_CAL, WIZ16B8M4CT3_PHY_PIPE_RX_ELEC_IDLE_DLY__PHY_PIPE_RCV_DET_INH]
0x0C WIZ16B8M4CT3_SERDES_RST
  [31] PHY_RESET_N — The PHY reset : Asserting this signal low will reset all PHY logic for the entire PHY with the exception of the APB registers and TAP controller. Note: Upon de-assertion, all PHY inputs must be driven as described in the PIPE specification for a PIPE reset.
  [30] PHY_EN_REFCLK — The PHY reference clock enable: When cmn_refclk_<p/m> is configured as a reference clock output, 1 = glitch-less enable of the reference clock output. 0 = glitch-less turn off reference clock output. Used in L1.x entry/exit protocol. Note: When outputting a derived reference clock from the PLL, it is recommended to drive phy_en_refclk low until the PHY has completed start-up and de-asserted pipe_l*_reset_ n for PIPE operation or asserted cmn_ready for Raw SERDES operation.. The clock will not be 'good' until the PHY has completed initial start-up.
  [29:28] PLL0_REFCLK_SEL — The PMA common PLL0 reference clock source select - 2'b00 - Selects cmn_refclk_<m/p> as reference clock source 2'b10 - Selects pma_cmn_refclk0_int (core_ref_clk) as reference clock source. 2'b11 - Selects pma_cmn_refclk1_int (core_ref1_clk) as reference clock source. Note: This field is write protected when register field ~iphy_reset_n is a '1'.
  [27] REFCLK_TERM_DIS — The PMA common differential reference clock termination disable - enables/disables termination for difference reference clock input (cmn_refclk_<p/m>). Must be set before the de-assertion of apb_preset_n/phy_reset_n. 1 = termination disabled 0 = termination enabled. Note: This field is write protected when register field ~iphy_reset_n is a '1'.
  [25:24] REFCLK_DIG_SEL — The Reference clock digital source select - Selects the reference clock source for the reference clock used in the PHY and PMA digital logic. 2'b00 - cmn_refclk_<p/m> device pins 2'b01 - Reserved 2'b10 - pma_cmn_refclk0_int (core_ref_clk) 2'b11 - pma_cmn_refclk1_in (core_ref1_clk) Note: This field is write protected when register field ~iphy_reset_n is a '1'.
  [23:22] PLL1_REFCLK_SEL — The PMA common PLL0 reference clock source select - 2'b00 - Selects cmn_refclk_<m/p> as reference clock source 2'b10 - Selects pma_cmn_refclk0_int (core_ref_clk) as reference clock source. 2'b11 - Selects pma_cmn_refclk1_int (core_ref1_clk) as reference clock source. Note: This field is write protected when register field ~iphy_reset_n is a '1'.
0x0C WIZ16B8M4CT3_XCVR_PSM_A3IN_TMR__XCVR_PSM_A2IN_TMR reset 0x100010
  [21:16] XCVR_PSM_A3IN_TMR_5_0 — A3 in delay state timer value : Value used for the timer when the power state machine is in the A3 in delay state. This timer delay is specified as the number of PSM clocks to count to implement the time required for tpsm_A3_in_del. Note, the smallest value this field is allowed to be is 6'h01. With that said, setting this field to a value smaller than the reset value will likely result in incorrect function.
  [5:0] XCVR_PSM_A2IN_TMR_5_0 — A2 in delay state timer value : Value used for the timer when the power state machine is in the A2 in delay state. This timer delay is specified as the number of PSM clocks to count to implement the time required for tpsm_A2_in_del. Note, the smallest value this field is allowed to be is 6'h01. With that said, setting this field to a value smaller than the reset value will likely result in incorrect function.
0x0C WIZ16B8M4CT3_RX_PSC_RDY__RX_PSC_CAL reset 0x10F
  [28] RX_PSC_RDY_12 — RX signal detect enable extend control
  [27] RX_PSC_RDY_11 — RX signal detect filter enable
  [26] RX_PSC_RDY_10 — RX LFPS detect filter enable
  [25] RX_PSC_RDY_9 — Reserved - spare
  [24] RX_PSC_RDY_8 — RX signal detect enable
  [23:21] RX_PSC_RDY_7_5 — Reserved - spare
  [20] RX_PSC_RDY_4 — RX equalizer engine enable
  [19] RX_PSC_RDY_3 — RX DFE equalization enable.
  [18] RX_PSC_RDY_2 — RX PI enable
  [17] RX_PSC_RDY_1 — RX e path enable (calibration and eye surf only)
  [16] RX_PSC_RDY_0 — RX enable
  [12] RX_PSC_CAL_12 — RX signal detect enable extend control
  [11] RX_PSC_CAL_11 — RX signal detect filter enable
  [10] RX_PSC_CAL_10 — RX LFPS detect filter enable
  [9] RX_PSC_CAL_9 — Reserved - spare
  [8] RX_PSC_CAL_8 — RX signal detect enable
  [7:5] RX_PSC_CAL_7_5 — Reserved - spare
  [4] RX_PSC_CAL_4 — RX equalizer engine enable
  [3] RX_PSC_CAL_3 — RX DFE equalization enable.
  [2] RX_PSC_CAL_2 — RX PI enable
  [1] RX_PSC_CAL_1 — RX e path enable (calibration and eye surf only)
  [0] RX_PSC_CAL_0 — RX enable
0x0C WIZ16B8M4CT3_PHY_PIPE_RX_ELEC_IDLE_DLY__PHY_PIPE_RCV_DET_INH reset 0x3C963D09
  [31:26] PHY_PIPE_RX_ELEC_IDLE_DLY_15_10 — PCIe PCS L1.x exit Rx electrical idle force fast count : Counter load value to hold PIPE Rx Electrical Idle high upon exit from L1.x. Counter is loaded and starts counting down after phy_l*_rx_elec_idle_det_en is asserted high. Default is 500 nsec. This counter accounts for time to power on just the analog Rx signal detect block. Based on reference clock cycles (25 MHz default). Minimum value = 6'd0.
  [25:16] PHY_PIPE_RX_ELEC_IDLE_DLY_9_0 — PCIe PCS L1.x exit Rx electrical idle force full count : Counter load value to hold PIPE Rx Electrical Idle high upon exit from L1.x when the PMA common was powered down. Counter is loaded and starts counting down upon de-assertion of PMA cmn_ref_clk_disable (upon de-assertion of phy_l*_ent_l1_x for first link). Default is 6 usec. This counter accounts for time to power on the bias and decap and only takes effect if the PMA was suspended. Based on reference clock cycles (25 MHz default). Minimum value = 10'd1.
  [15:0] PHY_PIPE_RCV_DET_INH_15_0 — PCS Receiver Detect Inhibit Counter Load Value: Counter load value to delay receiver detection request to PMA until PMA common mode is within the required range. The timer (running on divided reference clock from PMA) starts once the PMA common has completed startup. If receiver detect request is received while timer has not expired, the PCS will wait until the timer expires before signaling the request to the PMA. Load value is specified in multiples of 4x the divider reference clock period (typically 40 nsec for 100 MHz reference clock input frequency) for a 2.5 msec inhibit time.
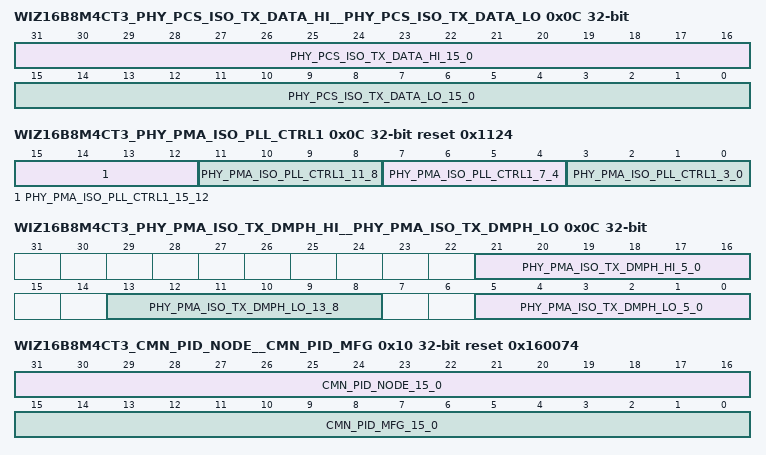
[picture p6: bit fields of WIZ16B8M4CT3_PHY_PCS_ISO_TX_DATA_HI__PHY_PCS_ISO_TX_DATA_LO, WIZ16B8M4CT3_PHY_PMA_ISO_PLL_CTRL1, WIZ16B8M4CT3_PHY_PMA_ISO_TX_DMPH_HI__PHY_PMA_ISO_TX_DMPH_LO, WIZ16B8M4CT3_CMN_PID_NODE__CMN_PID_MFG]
0x0C WIZ16B8M4CT3_PHY_PCS_ISO_TX_DATA_HI__PHY_PCS_ISO_TX_DATA_LO
  [31:16] PHY_PCS_ISO_TX_DATA_HI_15_0 — Drives pipe_tx_data[31:16] PHY input for the associated lane when in PHY macro and PMA isolation mode.
  [15:0] PHY_PCS_ISO_TX_DATA_LO_15_0 — Drives pipe_tx_data[15:0] PHY input for the associated lane when in PHY macro and PMA isolation mode.
0x0C WIZ16B8M4CT3_PHY_PMA_ISO_PLL_CTRL1 reset 0x1124
  [15:12] PHY_PMA_ISO_PLL_CTRL1_15_12 — Drives cmn_pll1_clk_datart1_div PMA input when in PMA isolation mode
  [11:8] PHY_PMA_ISO_PLL_CTRL1_11_8 — Drives cmn_pll1_clk_datart0_div PMA input when in PMA isolation mode
  [7:4] PHY_PMA_ISO_PLL_CTRL1_7_4 — Drives cmn_pll0_clk_datart1_div PMA input when in PMA isolation mode
  [3:0] PHY_PMA_ISO_PLL_CTRL1_3_0 — Drives cmn_pll0_clk_datart0_div PMA input when in PMA isolation mode
0x0C WIZ16B8M4CT3_PHY_PMA_ISO_TX_DMPH_HI__PHY_PMA_ISO_TX_DMPH_LO
  [21:16] PHY_PMA_ISO_TX_DMPH_HI_5_0 — Drives tx_deemphasis[17:12] PMA input for the associated lane when in PMA isolation mode or PHY isolation mode and lane is configured for Raw SerDes mode.
  [13:8] PHY_PMA_ISO_TX_DMPH_LO_13_8 — Drives tx_deemphasis[11:6] PMA input for the associated lane when in PMA isolation mode or PHY isolation mode and lane is configured for Raw SerDes mode.
  [5:0] PHY_PMA_ISO_TX_DMPH_LO_5_0 — Drives tx_deemphasis[5:0] PMA input for the associated lane when in PMA isolation mode or PHY isolation mode and lane is configured for Raw SerDes mode.
0x10 WIZ16B8M4CT3_CMN_PID_NODE__CMN_PID_MFG ro reset 0x160074
  [31:16] CMN_PID_NODE_15_0 — Product technology process node : This field contains the binary coded decimal numbers that represent the product technology node
  [15:0] CMN_PID_MFG_15_0 — Product technology manufacturer : This field contains the ASCII codes that represent the product technology manufacturer.
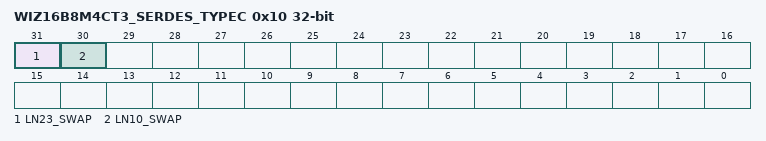
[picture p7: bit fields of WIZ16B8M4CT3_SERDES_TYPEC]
0x10 WIZ16B8M4CT3_SERDES_TYPEC
  [31] LN23_SWAP — The~iln23_swap will swap the lanes 2 and 3. That is all control for lane 2 will apply to lane 3 and vice versa. You cannot set ~iln23_swap to swap lanes in a link. That is If lanes 2 and 3 are used for a single link of PCIe, the ~iln23_swap must be '0'. Note: This field is write protected when register field ~i(reg_p2_enable|reg_p3_enable) is a '1'.
  [30] LN10_SWAP — The ~iln10_swap will swap the lanes 0 and 1. That is all control for lane 0 will apply to lane 1 and vice versa. You cannot set ~iln10_swap to swap lanes in a link. That is If lanes 0 and 1 are used for a single link of PCIe, the ~iln10_swap must be '0'. Note: This field is write protected when register field ~i(reg_p0_enable|reg_p1_enable) is a '1'.
